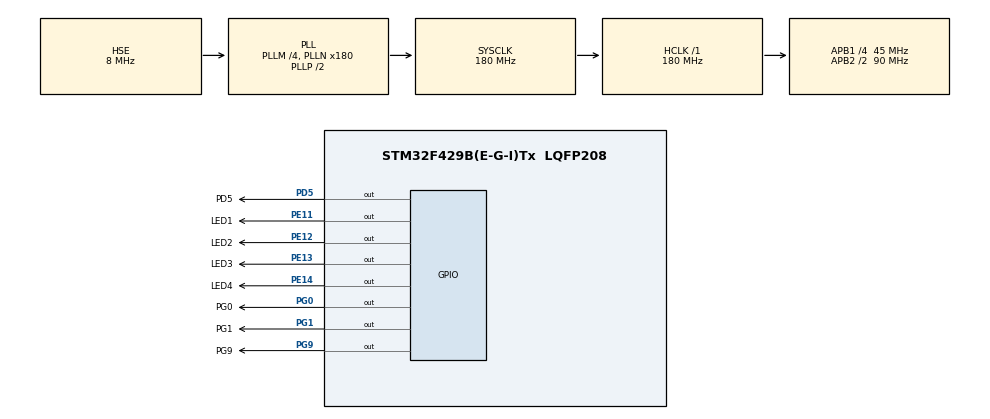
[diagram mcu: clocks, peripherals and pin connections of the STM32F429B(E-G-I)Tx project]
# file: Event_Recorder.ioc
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Mcu.Family=STM32F4
Mcu.Name=STM32F429B(E-G-I)Tx
Mcu.Package=LQFP208
NVIC.PriorityGroup=NVIC_PRIORITYGROUP_4
PA13.Mode=Trace_Synchro_4bits_JTAG
PA13.Signal=SYS_JTMS-SWDIO
PA14.Mode=Trace_Synchro_4bits_JTAG
PA14.Signal=SYS_JTCK-SWCLK
PA15.Mode=Trace_Synchro_4bits_JTAG
PA15.Signal=SYS_JTDI
PB3.Mode=Trace_Synchro_4bits_JTAG
PB3.Signal=SYS_JTDO-SWO
PD5.GPIO_Label=PD5
PD5.GPIO_PuPd=GPIO_PULLUP
PD5.Signal=GPIO_Output
PE11.GPIO_Label=LED1
PE11.GPIO_PuPd=GPIO_PULLUP
PE11.PinState=GPIO_PIN_SET
PE11.Signal=GPIO_Output
PE12.GPIO_Label=LED2
PE12.GPIO_PuPd=GPIO_PULLUP
PE12.PinState=GPIO_PIN_SET
PE12.Signal=GPIO_Output
PE13.GPIO_Label=LED3
PE13.GPIO_PuPd=GPIO_PULLUP
PE13.PinState=GPIO_PIN_SET
PE13.Signal=GPIO_Output
PE14.GPIO_Label=LED4
PE14.GPIO_PuPd=GPIO_PULLUP
PE14.PinState=GPIO_PIN_SET
PE14.Signal=GPIO_Output
PE2.Mode=Trace_Synchro_4bits_JTAG
PE2.Signal=SYS_TRACECLK
PE3.Mode=Trace_Synchro_4bits_JTAG
PE3.Signal=SYS_TRACED0
PE4.Mode=Trace_Synchro_4bits_JTAG
PE4.Signal=SYS_TRACED1
PE5.Mode=Trace_Synchro_4bits_JTAG
PE5.Signal=SYS_TRACED2
PE6.Mode=Trace_Synchro_4bits_JTAG
PE6.Signal=SYS_TRACED3
PG0.GPIO_Label=PG0
PG0.GPIO_PuPd=GPIO_PULLUP
PG0.PinState=GPIO_PIN_SET
PG0.Signal=GPIO_Output
PG1.GPIO_Label=PG1
PG1.GPIO_PuPd=GPIO_PULLDOWN
PG1.Signal=GPIO_Output
PG9.GPIO_Label=PG9
PG9.GPIO_PuPd=GPIO_PULLDOWN
PG9.Signal=GPIO_Output
PH0/OSC_IN.Mode=HSE-External-Oscillator
PH0/OSC_IN.Signal=RCC_OSC_IN
PH1/OSC_OUT.Mode=HSE-External-Oscillator
PH1/OSC_OUT.Signal=RCC_OSC_OUT
ProjectManager.HeapSize=0x200
ProjectManager.StackSize=0x400
ProjectManager.TargetToolchain=MDK-ARM V5.32
RCC.48MHZClocksFreq_Value=90000000
RCC.AHBFreq_Value=180000000
RCC.APB1CLKDivider=RCC_HCLK_DIV4
RCC.APB1Freq_Value=45000000
RCC.APB1TimFreq_Value=90000000
RCC.APB2CLKDivider=RCC_HCLK_DIV2
RCC.APB2Freq_Value=90000000
RCC.APB2TimFreq_Value=180000000
RCC.CortexFreq_Value=180000000
RCC.HCLKFreq_Value=180000000
RCC.HSE_VALUE=8000000
RCC.HSI_VALUE=16000000
RCC.LSE_VALUE=32768
RCC.PLLM=4
RCC.PLLN=180
RCC.PLLSourceVirtual=RCC_PLLSOURCE_HSE
RCC.SYSCLKFreq_VALUE=180000000
RCC.SYSCLKSource=RCC_SYSCLKSOURCE_PLLCLK
RCC.VCOOutputFreq_Value=360000000
board=custom

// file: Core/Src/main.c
/* USER CODE BEGIN Header */
/**
  ******************************************************************************
  * @file           : main.c
  * @brief          : Main program body
  ******************************************************************************
  * @attention
  *
  * Copyright (c) 2023 STMicroelectronics.
  * All rights reserved.
  *
  * This software is licensed under terms that can be found in the LICENSE file
  * in the root directory of this software component.
  * If no LICENSE file comes with this software, it is provided AS-IS.
  *
  ******************************************************************************
  */
/* USER CODE END Header */
#include "main.h"
#include "gpio.h"

/* USER CODE BEGIN Includes */
#include "EventRecorder.h"
#include "string.h"
#include "stdio.h"
/* USER CODE END Includes */

void SystemClock_Config(void);

int main(void)
{

  /* MCU Configuration--------------------------------------------------------*/

  /* Reset of all peripherals, Initializes the Flash interface and the Systick. */
  HAL_Init();

  /* Configure the system clock */
  SystemClock_Config();

  /* Initialize all configured peripherals */
  MX_GPIO_Init();
  /* USER CODE BEGIN 2 */
  EventRecorderInitialize(EventRecordAll, 1U);
  EventRecorderStart();

  /*
    HAL_GPIO_WritePin(PG9_GPIO_Port, PG9_Pin, GPIO_PIN_RESET);
    HAL_GPIO_WritePin(PG0_GPIO_Port, PG0_Pin, GPIO_PIN_SET);
    HAL_GPIO_WritePin(PG1_GPIO_Port, PG1_Pin, GPIO_PIN_RESET);
    HAL_GPIO_WritePin(PD5_GPIO_Port, PD5_Pin, GPIO_PIN_RESET);
    */
  /* USER CODE END 2 */

  /* Infinite loop */
  /* USER CODE BEGIN WHILE */
  while (1)
  {
    EventStartAv(0, 1, 2);
    printf("STDOUT & Event_Statistics & float[%.2f] test\n", 3.1415);
    /*
    HAL_GPIO_TogglePin(LED1_GPIO_Port, LED1_Pin);
    HAL_GPIO_TogglePin(LED2_GPIO_Port, LED2_Pin);
    HAL_GPIO_TogglePin(LED3_GPIO_Port, LED3_Pin);
    HAL_GPIO_TogglePin(LED4_GPIO_Port, LED4_Pin);
    HAL_GPIO_WritePin(PD5_GPIO_Port, PD5_Pin, GPIO_PIN_SET);    // rising edge
    HAL_GPIO_WritePin(PD5_GPIO_Port, PD5_Pin, GPIO_PIN_RESET);
      */
    HAL_Delay(2000);
    EventStopAv(0, 3, 4);
    /*
    EventRecord2(EventID(EventLevelDetail, COMPONENT_1, MSG_1), 1, 2);
    EventRecord4(EventID(EventLevelAPI, COMPONENT_2, MSG_2), 1, 2, 3, 4);
    EventRecordData(EventID(EventLevelDetail, COMPONENT_1, MSG_2), "1234567890", strlen("1234567890"));
    */
    /* USER CODE END WHILE */

  }
}

void SystemClock_Config(void)
{
  RCC_OscInitTypeDef RCC_OscInitStruct = {0};
  RCC_ClkInitTypeDef RCC_ClkInitStruct = {0};

  /** Configure the main internal regulator output voltage
  */
  __HAL_RCC_PWR_CLK_ENABLE();
  __HAL_PWR_VOLTAGESCALING_CONFIG(PWR_REGULATOR_VOLTAGE_SCALE1);

  /** Initializes the RCC Oscillators according to the specified parameters
  * in the RCC_OscInitTypeDef structure.
  */
  RCC_OscInitStruct.OscillatorType = RCC_OSCILLATORTYPE_HSE;
  RCC_OscInitStruct.HSEState = RCC_HSE_ON;
  RCC_OscInitStruct.PLL.PLLState = RCC_PLL_ON;
  RCC_OscInitStruct.PLL.PLLSource = RCC_PLLSOURCE_HSE;
  RCC_OscInitStruct.PLL.PLLM = 4;
  RCC_OscInitStruct.PLL.PLLN = 180;
  RCC_OscInitStruct.PLL.PLLP = RCC_PLLP_DIV2;
  RCC_OscInitStruct.PLL.PLLQ = 4;
  if (HAL_RCC_OscConfig(&RCC_OscInitStruct) != HAL_OK)
  {
    Error_Handler();
  }

  /** Activate the Over-Drive mode
  */
  if (HAL_PWREx_EnableOverDrive() != HAL_OK)
  {
    Error_Handler();
  }

  /** Initializes the CPU, AHB and APB buses clocks
  */
  RCC_ClkInitStruct.ClockType = RCC_CLOCKTYPE_HCLK|RCC_CLOCKTYPE_SYSCLK
                              |RCC_CLOCKTYPE_PCLK1|RCC_CLOCKTYPE_PCLK2;
  RCC_ClkInitStruct.SYSCLKSource = RCC_SYSCLKSOURCE_PLLCLK;
  RCC_ClkInitStruct.AHBCLKDivider = RCC_SYSCLK_DIV1;
  RCC_ClkInitStruct.APB1CLKDivider = RCC_HCLK_DIV4;
  RCC_ClkInitStruct.APB2CLKDivider = RCC_HCLK_DIV2;

  if (HAL_RCC_ClockConfig(&RCC_ClkInitStruct, FLASH_LATENCY_5) != HAL_OK)
  {
    Error_Handler();
  }
}

void Error_Handler(void)
{
  __disable_irq();
  while (1)
  {
  }
}
